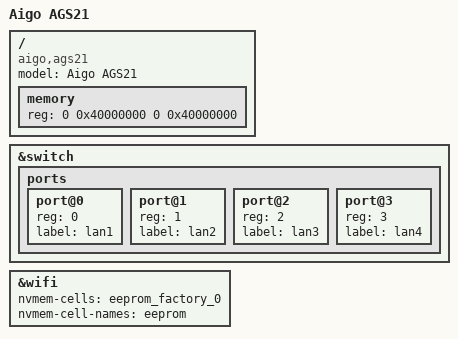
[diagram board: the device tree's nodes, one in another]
// SPDX-License-Identifier: GPL-2.0-or-later OR MIT
/dts-v1/;
#include "mt7981b-cmcc-rax3000m-emmc.dts"

/ {
    model = "Aigo AGS21";
    compatible = "aigo,ags21", "mediatek,mt7981";
    memory { reg = <0 0x40000000 0 0x40000000>; };
};

/* Factory partition and MAC offsets match the inspected AGS21 eMMC.
 * Retain the RAX3000M eMMC pin, LED and storage configuration reported
 * working on this hardware, and the four ports from the supplied FDT.
 */
&switch {
    ports {
        port@0 { reg = <0>; label = "lan1"; };
        port@1 { reg = <1>; label = "lan2"; };
        port@2 { reg = <2>; label = "lan3"; };
        port@3 { reg = <3>; label = "lan4"; };
    };
};

&wifi {
    nvmem-cells = <&eeprom_factory_0>;
    nvmem-cell-names = "eeprom";
    status = "okay";
};
